# MSS_DEBUGSS register map
Vendor: Texas Instruments
Peripheral module from a debugger description file (folder awr29xx).
Registers are 32-bit, read-write, no defined reset value unless marked. A register's access mark holds for its fields unless they carry their own. Offsets are as the file gives them; lines under a group give offsets from that group; [hi:lo] are bit positions; {n}, {i} and the like mark numbered series; 'fields as' and 'values as' point back to an identical list; <NAME> marks a mode.

## MSS_DEBUGSS (part 1 of 2)
0x00 ONEMCU_APB_BASE ro — Start Address of ROM Table
  [31:0] ONEMCU_APB_BASE — OneMCU APB Space : Start Address of ROM Table
0xFFC ONEMCU_APB_BASE_END ro — End Address of ROM Table
  [31:0] ONEMCU_APB_BASE_END — OneMCU APB Space : Endt Address of ROM Table
0x1000 ONEMCU_CTI_CONTROL — http://infocenter.arm.com/help/topic/com.arm.doc.ddi0314h/Chdjefbi.html http://infocenter.arm.com/help/topic/com.arm.doc.ddi0314h/Chdefejc.html
  [31:0] ONEMCU_CTI_CONTROL — http://infocenter.arm.com/help/topic/com.arm.doc.ddi0480e/CHDGDIHE.html http://infocenter.arm.com/help/topic/com.arm.doc.ddi0480e/CHDHBDIA.html
0x1010 ONEMCU_CTI_INTACK wo
0x1014 ONEMCU_CTI_APPSET
0x1018 ONEMCU_CTI_APPCLEAR wo
0x101C ONEMCU_CTI_APPPULSE wo
{0x1020+4i} ONEMCU_CTI_INEN{i} (i=0..7)
{0x10A0+4i} ONEMCU_CTI_OUTEN{i} (i=0..7)
0x1130 ONEMCU_CTI_TRIGINSTATUS ro
0x1134 ONEMCU_CTI_TRIGOUTSTATUS ro
0x1138 ONEMCU_CTI_CHINSTATUS ro
0x113C ONEMCU_CTI_CHOUTSTATUS ro
0x1140 ONEMCU_CTI_GATE
0x1144 ONEMCU_CTI_ASICCTL
0x1EDC ONEMCU_CTI_ITCHINACK wo
0x1EE0 ONEMCU_CTI_ITTRIGINACK wo
0x1EE4 ONEMCU_CTI_ITCHOUT wo
0x1EE8 ONEMCU_CTI_ITTRIGOUT wo
0x1EEC ONEMCU_CTI_ITCHOUTACK ro
0x1EF0 ONEMCU_CTI_ITTRIGOUTACK ro
0x1EF4 ONEMCU_CTI_ITCHIN ro
0x1EF8 ONEMCU_CTI_ITTRIGIN ro
0x1F00 ONEMCU_CTI_ITCTRL
0x1FA0 ONEMCU_CTI_Claim_Tag_Set
0x1FA4 ONEMCU_CTI_Claim_Tag_Clear
0x1FB0 ONEMCU_CTI_Lock_Access_Register wo
0x1FB4 ONEMCU_CTI_Lock_Status_Register ro
0x1FB8 ONEMCU_CTI_Authentication_Status ro
0x1FC8 ONEMCU_CTI_Device_ID ro
0x1FCC ONEMCU_CTI_Device_Type_Identifier ro
{0x1FC0+4i} ONEMCU_CTI_PeripheralID{i} ro (i=4..7)
{0x1FE0+4i} ONEMCU_CTI_PeripheralID{i} ro (i=0..3)
{0x1FF0+4i} ONEMCU_CTI_Component_ID{i} ro (i=0..3)
0x2000 ONEMCU_TPIU_SPORTSZ ro — Supported port sizes
0x2004 ONEMCU_TPIU_CPORTSZ — Current port size
0x2100 ONEMCU_TPIU_STRIGM ro — Supported trigger modes
0x2104 ONEMCU_TPIU_TRIGCNT — Trigger counter value
0x2108 ONEMCU_TPIU_TRIGMUL — Trigger multiplier
0x2200 ONEMCU_TPIU_STSTPTRN ro — Supported test pattern/modes
0x2204 ONEMCU_TPIU_CTSTPTRN — Current test pattern/mode
0x2208 ONEMCU_TPIU_TPRCNTR — Test pattern repeat counter
0x2300 ONEMCU_TPIU_FFSTS ro — Formatter and flush status
0x2304 ONEMCU_TPIU_FFCTRL — Formatter and flush control
0x2308 ONEMCU_TPIU_FSCNTR — Formatter synchronization counter
0x2400 ONEMCU_TPIU_EXCTLIN ro — EXTCTL In Port
0x2404 ONEMCU_TPIU_EXCTLOUT — EXTCTL Out Port
0x2EE4 ONEMCU_TPIU_ITTRFLINACK wo — Integration Register, ITTRFLINACK
0x2EE8 ONEMCU_TPIU_ITTRFLIN ro — Integration Register, ITTRFLIN
0x2EEC ONEMCU_TPIU_ITATBDATA0 ro — Integration Register, ITATBDATA0
0x2EF0 ONEMCU_TPIU_ITATBCTR2 wo — Integration Register, ITATBCTR2
0x2EF4 ONEMCU_TPIU_ITATBCTR1 ro — Integration Register, ITATBCTR1
0x2EF8 ONEMCU_TPIU_ITATBCTR0 ro — Integration Register, ITATBCTR0
0x2F00 ONEMCU_TPIU_ITCTRL — Integration Mode Control Register
0x2FA0 ONEMCU_TPIU_CLAIMSET — Claim Tag Set
0x2FA4 ONEMCU_TPIU_CLAIMCLR — Claim Tag Clear
0x2FB0 ONEMCU_TPIU_LAR ro — Lock status
0x2FB4 ONEMCU_TPIU_LSR wo — Lock Access
0x2FB8 ONEMCU_TPIU_AUTHSTATUS ro — Authentication status
0x2FC8 ONEMCU_TPIU_DEVID ro — Device ID
0x2FCC ONEMCU_TPIU_DEVTYPE ro — Device type identifier
{0x2FC0+4i} ONEMCU_TPIU_PIDR{i} ro (i=4..7) — Peripheral ID{i}
{0x2FE0+4i} ONEMCU_TPIU_PIDR{i} ro (i=0..3) — Peripheral ID{i}
{0x2FF0+4i} ONEMCU_TPIU_CIDR{i} ro (i=0..3) — Component ID{i}
0x10000 GEM_ADTF_CSR
  [31:0] GEM_ADTF_CSR — Control & Status Register
0x10400 GEM_ADTF_TRACE_ID
  [31:0] GEM_ADTF_TRACE_ID — Trace ID
0x10FA0 GEM_ADTF_MR_CLAIMSET — Claim Tag Set Register
0x10FA4 GEM_ADTF_MR_CLAIMCLR — Claim Tag Clear Register
0x10FB0 GEM_ADTF_MR_LOCKACCESS — Lock Access Register
0x10FB4 GEM_ADTF_MR_LOCKSTATUS — Lock Status Register
0x10FB8 GEM_ADTF_MR_AUTHSTATUS — Authentication Status Register
0x10FC8 GEM_ADTF_MR_DEVID — Device Identifier
0x10FCC GEM_ADTF_MR_DEVTYPE — Device Type Register
{0x10FC0+4i} GEM_ADTF_PERIP_ID{i} (i=4..7)
  [31:0] GEM_ADTF_PERIP_ID{i} — Peripheral ID
{0x10FE0+4i} GEM_ADTF_PERIP_ID{i} (i=0..3)
  [31:0] GEM_ADTF_PERIP_ID{i} — Peripheral ID
{0x10FF0+4i} GEM_ADTF_COMP_ID{i} (i=0..3)
  [31:0] GEM_ADTF_COMP_ID{i} — Component ID
0x11000 GEM_ATB_IDFILTER0 — ID filtering for ATB master port 0
  [31:0] GEM_ATB_IDFILTER0 — http://infocenter.arm.com/help/topic/com.arm.doc.ddi0480e/CHDFGIED.html http://infocenter.arm.com/help/topic/com.arm.doc.ddi0480e/CHDBDCII.html
0x11004 GEM_ATB_IDFILTER1 — ID filtering for ATB master port 1
0x11EF8 GEM_ATB_ITATBCTR1 ro — Integration Mode ATB Control 1 Register
0x11EFC GEM_ATB_ITATBCTR0 wo — Integration Mode ATB Control 0 Register
0x11F00 GEM_ATB_ITCTRL — Integration Mode Control Register
0x11FA0 GEM_ATB_CLAIMSET — Claim Tag Set Register
0x11FA4 GEM_ATB_CLAIMCLR — Claim Tag Clear Register
0x11FB0 GEM_ATB_LAR wo — Lock Access Register
0x11FB4 GEM_ATB_LSR ro — Lock Status
0x11FB8 GEM_ATB_AUTHSTATUS ro — Authentication Status Register
0x11FC8 GEM_ATB_DEVID ro — Device Configuration Register
0x11FCC GEM_ATB_DEVTYPE ro — Device Type Identifier Register
0x11FD0 GEM_ATB_PIDR4 ro — Peripheral ID4 Register
{0x11FD0+4i} GEM_ATB_RESERVED{i} ro (i=1..3) — Reserved
{0x11FE0+4i} GEM_ATB_PIDR{i} ro (i=0..3) — Peripheral ID{i} Register
{0x11FF0+4i} GEM_ATB_CIDR{i} ro (i=0..3) — Component ID{i} Register
0x12000 MSS_ATB_IDFILTER0 — ID filtering for ATB master port 0
  [31:0] MSS_ATB_IDFILTER0 — http://infocenter.arm.com/help/topic/com.arm.doc.ddi0480e/CHDFGIED.html http://infocenter.arm.com/help/topic/com.arm.doc.ddi0480e/CHDBDCII.html
0x12004 MSS_ATB_IDFILTER1 — ID filtering for ATB master port 1
0x12EF8 MSS_ATB_ITATBCTR1 ro — Integration Mode ATB Control 1 Register
0x12EFC MSS_ATB_ITATBCTR0 wo — Integration Mode ATB Control 0 Register
0x12F00 MSS_ATB_ITCTRL — Integration Mode Control Register
0x12FA0 MSS_ATB_CLAIMSET — Claim Tag Set Register
0x12FA4 MSS_ATB_CLAIMCLR — Claim Tag Clear Register
0x12FB0 MSS_ATB_LAR wo — Lock Access Register
0x12FB4 MSS_ATB_LSR ro — Lock Status
0x12FB8 MSS_ATB_AUTHSTATUS ro — Authentication Status Register
0x12FC8 MSS_ATB_DEVID ro — Device Configuration Register
0x12FCC MSS_ATB_DEVTYPE ro — Device Type Identifier Register
0x12FD0 MSS_ATB_PIDR4 ro — Peripheral ID4 Register
{0x12FD0+4i} MSS_ATB_RESERVED{i} ro (i=1..3) — Reserved
{0x12FE0+4i} MSS_ATB_PIDR{i} ro (i=0..3) — Peripheral ID{i} Register
{0x12FF0+4i} MSS_ATB_CIDR{i} ro (i=0..3) — Component ID{i} Register
0x13004 ETB_RDP ro — ETBRAMDepthRegister
  [31:0] ETB_RDP — http://infocenter.arm.com/help/topic/com.arm.doc.ddi0480e/CHDIEIAJ.html http://infocenter.arm.com/help/topic/com.arm.doc.ddi0480e/CHDDBEHG.html
0x1300C ETB_STS ro — ETBStatusRegister
0x13010 ETB_RRD ro — ETBRAMReadDataRegister
0x13014 ETB_RRP — ETBRAMReadPointerRegister
0x13018 ETB_RWP — ETBRAMWritePointerRegister
0x1301C ETB_TRG — ETBTriggerCounterRegister
0x13020 ETB_CTL — ETBControlRegister
0x13024 ETB_RWD wo — ETBRAMWriteDataRegister
0x13300 ETB_FFSR ro — ETBFormatterandFlushStatusRegister
0x13304 ETB_FFCR — ETBFormatterandFlushControlRegister
0x13EE0 ETB_ITMISCOP0 wo — IntegrationTestMiscellaneousOutputRegister0
0x13EE4 ETB_ITTRFLINACK wo — IntegrationTestTriggerInandFlushInAcknowledgeRegister
0x13EE8 ETB_ITTRFLIN ro — IntegrationTestTriggerInandFlushInRegister
0x13EEC ETB_ITATBDATA0 ro — IntegrationTestATBDataRegister0
0x13EF0 ETB_ITATBCTR2 wo — IntegrationTestATBControlRegister2
0x13EF4 ETB_ITATBCTR1 ro — IntegrationTestATBControlRegister1
0x13EF8 ETB_ITATBCTR0 ro — IntegrationTestATBControlRegister0
0x13F00 ETB_ITCTRL — IntegrationModeControlRegister
0x13FA0 ETB_CLAIMSET — ClaimTagSetRegister
0x13FA4 ETB_CLAIMCLR — ClaimTagClearRegister
0x13FB0 ETB_LAR wo — LockAccessRegister
0x13FB4 ETB_LSR ro — LockStatusRegister
0x13FB8 ETB_AUTHSTATUS ro — AuthenticationStatusRegister
0x13FC8 ETB_DEVID ro — DeviceConfigurationRegister
0x13FCC ETB_DEVTYPE ro — DeviceTypeIdentifierRegister
0x13FD0 ETB_PIDR4 ro — PeripheralID4Register
{0x13FC4+4i} ETB_RESERVED{i} ro (i=4..6) — Reserved
{0x13FE0+4i} ETB_PIDR{i} ro (i=0..3) — PeripheralID{i}Register
{0x13FF0+4i} ETB_CIDR{i} ro (i=0..3) — ComponentID{i}Register
0x14000 DSS_CM4_ATB_IDFILTER0 — ID filtering for ATB master port 0
  [31:0] DSS_CM4_ATB_IDFILTER0 — http://infocenter.arm.com/help/topic/com.arm.doc.ddi0480e/CHDFGIED.html http://infocenter.arm.com/help/topic/com.arm.doc.ddi0480e/CHDBDCII.html
0x14004 DSS_CM4_ATB_IDFILTER1 — ID filtering for ATB master port 1
0x14EF8 DSS_CM4_ATB_ITATBCTR1 ro — Integration Mode ATB Control 1 Register
0x14EFC DSS_CM4_ATB_ITATBCTR0 wo — Integration Mode ATB Control 0 Register
0x14F00 DSS_CM4_ATB_ITCTRL — Integration Mode Control Register
0x14FA0 DSS_CM4_ATB_CLAIMSET — Claim Tag Set Register
0x14FA4 DSS_CM4_ATB_CLAIMCLR — Claim Tag Clear Register
0x14FB0 DSS_CM4_ATB_LAR wo — Lock Access Register
0x14FB4 DSS_CM4_ATB_LSR ro — Lock Status
0x14FB8 DSS_CM4_ATB_AUTHSTATUS ro — Authentication Status Register
0x14FC8 DSS_CM4_ATB_DEVID ro — Device Configuration Register
0x14FCC DSS_CM4_ATB_DEVTYPE ro — Device Type Identifier Register
0x14FD0 DSS_CM4_ATB_PIDR4 ro — Peripheral ID4 Register
{0x14FD0+4i} DSS_CM4_ATB_RESERVED{i} ro (i=1..3) — Reserved
{0x14FE0+4i} DSS_CM4_ATB_PIDR{i} ro (i=0..3) — Peripheral ID{i} Register
{0x14FF0+4i} DSS_CM4_ATB_CIDR{i} ro (i=0..3) — Component ID{i} Register
0x15000 HSM_CM4_ATB_IDFILTER0 — ID filtering for ATB master port 0
  [31:0] HSM_CM4_ATB_IDFILTER0 — http://infocenter.arm.com/help/topic/com.arm.doc.ddi0480e/CHDFGIED.html http://infocenter.arm.com/help/topic/com.arm.doc.ddi0480e/CHDBDCII.html
0x15004 HSM_CM4_ATB_IDFILTER1 — ID filtering for ATB master port 1
0x15EF8 HSM_CM4_ATB_ITATBCTR1 ro — Integration Mode ATB Control 1 Register
0x15EFC HSM_CM4_ATB_ITATBCTR0 wo — Integration Mode ATB Control 0 Register
0x15F00 HSM_CM4_ATB_ITCTRL — Integration Mode Control Register
0x15FA0 HSM_CM4_ATB_CLAIMSET — Claim Tag Set Register
0x15FA4 HSM_CM4_ATB_CLAIMCLR — Claim Tag Clear Register
0x15FB0 HSM_CM4_ATB_LAR wo — Lock Access Register
0x15FB4 HSM_CM4_ATB_LSR ro — Lock Status
0x15FB8 HSM_CM4_ATB_AUTHSTATUS ro — Authentication Status Register
0x15FC8 HSM_CM4_ATB_DEVID ro — Device Configuration Register
0x15FCC HSM_CM4_ATB_DEVTYPE ro — Device Type Identifier Register
0x15FD0 HSM_CM4_ATB_PIDR4 ro — Peripheral ID4 Register
{0x15FD0+4i} HSM_CM4_ATB_RESERVED{i} ro (i=1..3) — Reserved
{0x15FE0+4i} HSM_CM4_ATB_PIDR{i} ro (i=0..3) — Peripheral ID{i} Register
{0x15FF0+4i} HSM_CM4_ATB_CIDR{i} ro (i=0..3) — Component ID{i} Register
0x16C04 STMDMASTARTR wo — ARM® System Trace Macrocell Programmers’ Model Architecture Specification
0x16C08 STMDMASTOPR wo — ARM® System Trace Macrocell Programmers’ Model Architecture Specification
0x16C0C STMDMASTATR ro — ARM® System Trace Macrocell Programmers’ Model Architecture Specification
0x16C10 STMDMACTLR 4-bit — Controls the DMA transfer request mechanism.
  [3:2] SENS — Determines the sensitivity of the DMA request to the current buffer level in the STM: 0b00 Buffer is <25% full. 0b01 Buffer is <50% full. 0b10 Buffer is <75% full. 0b11 Buffer is <100% full.
0x16CFC STMDMAIDR ro — ARM® System Trace Macrocell Programmers’ Model Architecture Specification
0x16D00 STMHEER — ARM® System Trace Macrocell Programmers’ Model Architecture Specification
0x16D20 STMHETER — ARM® System Trace Macrocell Programmers’ Model Architecture Specification
0x16D60 STMHEBSR — ARM® System Trace Macrocell Programmers’ Model Architecture Specification
0x16D64 STMHEMCR — ARM® System Trace Macrocell Programmers’ Model Architecture Specification
0x16D68 STMHEEXTMUXR 8-bit — Hardware Event External Multiplex Control Register
  [7:0] EXTMUX — Specifies the value that the optional external multiplexing logic uses to select the hardware events to connect to the STM. The value of this register is output from the STM on the HEEXTMUX[7:0] signals. The behavior of the multiplexing logic is IMPLEMENTATION DEFINED. This field is reset to zero.
0x16DF4 STMHEMASTR 16-bit ro — Hardware Event Master Number Register
  [15:0] MASTER — The STPv2 master number for the hardware event trace: 0x80 Hardware events are associated with master ID 0x80.
0x16DF8 STMHEFEAT1R 31-bit ro — Hardware Event Features 1 Register
  [30:28] HEEXTMUXSIZE — The size of the STMHEEXTMUXR.EXTMUX bit field: 0b011 8 bits wide.
  [23:15] NUMHE — The number of hardware events supported by the STM: 0b001000000 64 hardware events.
  [5:4] HECOMP — Data compression on hardware event tracing support: 0b11 Programmable data compression support. The STM implements the STMHEMCR.COMPEN bit.
  [3] HEMASTR — Specifies the STMHEMASTR support: 0b0 The STMHEMASTR is read-only.
  [2] HEERR — Hardware event error detection support: 0b1 Implemented. The STM implements the STMHEMCR.ERRDETECT bit.
  [0] HETER — Specifies the STMHETER support: 0b1 Implemented.
0x16DFC STMHEIDR 12-bit ro — Hardware Event ID Register
  [11:8] VENDSPEC — Identifies vendor-specific modifications or mappings: 0b0000 Vendor-specific information.
  [7:4] CLASSREV — Identifies the revision of the programmers model: 0b0001 Revision.
  [3:0] CLASS — Identifies the programmers model: 0b0001 Hardware event control.
0x16E00 STMSPER — ARM® System Trace Macrocell Programmers’ Model Architecture Specification
0x16E20 STMSPTER — ARM® System Trace Macrocell Programmers’ Model Architecture Specification
0x16E60 STMSPSCR — ARM® System Trace Macrocell Programmers’ Model Architecture Specification
0x16E64 STMSPMSCR — ARM® System Trace Macrocell Programmers’ Model Architecture Specification
0x16E68 STMSPOVERRIDER — ARM® System Trace Macrocell Programmers’ Model Architecture Specification
0x16E6C STMSPMOVERRIDER — ARM® System Trace Macrocell Programmers’ Model Architecture Specification
0x16E70 STMSPTRIGCSR — ARM® System Trace Macrocell Programmers’ Model Architecture Specification
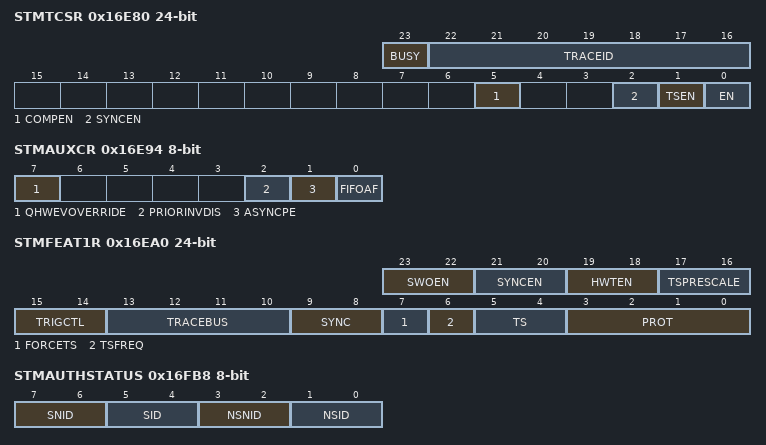
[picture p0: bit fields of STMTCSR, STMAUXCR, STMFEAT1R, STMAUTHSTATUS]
0x16E80 STMTCSR 24-bit — Trace Control and Status Register
  [23] BUSY — Indicates whether the STM is busy, for example the STM trace FIFO is not empty: 0b0 Not busy. 0b1 Busy.
  [22:16] TRACEID — ATB trace ID. Setting this value to all zeroes or to a value greater than 0x6F might result in UNPREDICTABLE tracing. Reset value of this bit field is UNKNOWN.
  [5] COMPEN — Compression enable for stimulus ports: 0b0 Disabled, the STM transmits data transfers based on the size of the transaction. 0b1 Enabled, the STM compresses data transfers to save bandwidth.
  [2] SYNCEN — The STM implements the STMSYNCR, so this bit is Read As One. 0b1 The STM implements the STMSYNCR.
  [1] TSEN — Determines whether to ignore timestamp requests: 0b0 Disable timestamping. The STM ignores requests for timestamp generation, and treats stimulus port writes that select timestamping as if timestamping were not selected. 0b1 Enable timestamping. If stimulus writes select timestamping, the STM outputs a timestamp according to STPv2.
  [0] EN — Global STM enable: 0b0 Disabled 0b1 Enabled.
0x16E84 STMTSSTIMR wo — ARM® System Trace Macrocell Programmers’ Model Architecture Specification
0x16E8C STMTSFREQR — ARM® System Trace Macrocell Programmers’ Model Architecture Specification
0x16E90 STMSYNCR — ARM® System Trace Macrocell Programmers’ Model Architecture Specification
0x16E94 STMAUXCR 8-bit — Auxiliary Control Register
  [7] QHWEVOVERRIDE — Low-power interface override when hardware event tracing is enabled: 0b0 The STM can accept a quiescence request on the STM low-power interface when the STMHEMCR.EN bit is set to 0b1. 0b1 If the STMHEMCR.EN bit is set to 0b1, all quiescence requests on the STM low-power interface are denied. Reset value is 0b0.
  [2] PRIORINVDIS — Controls arbitration between the AXI interface and the hardware event observation interface during flush: 0b0 Priority inversion. When the AXI flush completes, the hardware event observation interface gets priority until the hardware event observation interface flush completes. 0b1 Priority inversion disabled. The AXI always has priority over the hardware event observation interface. Reset value is 0b0.
  [1] ASYNCPE — ASYNC priority: 0b0 Always lower than trace. 0b1 Escalates on second synchronization request. Reset value is 0b0.
  [0] FIFOAF — Auto-flush: 0b0 Disabled. 0b1 Enabled. The STM automatically drains all data even if the ATB interface is not fully utilized. Reset value is 0b0.
0x16EA0 STMFEAT1R 24-bit ro — STM Features 1 Register
  [23:22] SWOEN — Specifies the STMTCSR.SWOEN bit support: 0b01 Not implemented.
  [21:20] SYNCEN — Specifies the STMTCSR.SYNCEN bit support: 0b10 Implemented but always reads as 0b1.
  [19:18] HWTEN — Specifies the STMTCSR.HWTEN bit support: 0b01 Not implemented.
  [17:16] TSPRESCALE — Timestamp prescale support: 0b01 Not implemented.
  [15:14] TRIGCTL — Trigger control support: 0b10 Multi-shot and single-shot triggers supported, the STM implements the STMTRIGCSR.
  [13:10] TRACEBUS — Trace bus support: 0b0001 CoreSight ATB plus ATB trigger support implemented, the STM implements the STMTCSR.TRACEID and STMTRIGCSR.ATBTRIGEN bit fields.
  [9:8] SYNC — Specifies the STMSYNCR support: 0b11 Implemented with MODE control.
  [7] FORCETS — Specifies the STMTSSTIMR support: 0b1 The STM implements the STMTSSTIMR.FORCETS bit.
  [6] TSFREQ — Timestamp frequency indication configuration: 0b1 The STMTSFREQR is read-write.
  [5:4] TS — Timestamp support: 0b01 Absolute timestamps implemented.
  [3:0] PROT — Protocol: 0b0001 STPv2 protocol.
0x16EA4 STMFEAT2R 18-bit ro — STM Features 2 Register
  [17:16] SPTYPE — Stimulus port type support: 0b01 Only extended stimulus ports.
  [15:12] DSIZE — Fundamental data size: 0b0001 64-bit data.
  [10:9] SPTRTYPE — Stimulus port transaction type support: 0b10 Both invariant timing and guaranteed transactions.
  [8:7] PRIVMASK — Specifies the STMPRIVMASKR support: 0b01 Not implemented.
  [6] SPOVERRIDE — Specifies the STMSPOVERRIDER support: 0b1 STMSPOVERRIDER and STMSPMOVERRIDER implemented.
  [5:4] SPCOMP — Data compression on stimulus ports support: 0b11 Data compression support is programmable, the STM implements the STMTCSR.COMPEN bit.
  [2] SPER — Specifies the STMSPER presence: 0b0 Implemented.
  [1:0] SPTER — Specifies the STMSPTER support: 0b10 Implemented.
0x16EA8 STMFEAT3R 7-bit ro — STM Features 3 Register
  [6:0] NUMMAST — The number of stimulus port masters implemented minus 1: 0b1111111 128 ports.
0x16EE8 STMITTRIGGER 4-bit wo — Integration Test for Cross-Trigger Outputs Register
  [3] ASYNCOUT_W — Sets the value of the ASYNCOUT output signal in integration mode: 0b1 Drive logic 0b1. 0b0 Drive logic 0b0.
  [2] TRIGOUTHETE_W — Sets the value of the TRIGOUTHETE output signal in integration mode: 0b1 Drive logic 0b1. 0b0 Drive logic 0b0.
  [1] TRIGOUTSW_W — Sets the value of the TRIGOUTSW output signal in integration mode: 0b1 Drive logic 0b1. 0b0 Drive logic 0b0.
  [0] TRIGOUTSPTE_W — Sets the value of the TRIGOUTSPTE output signal in integration mode: 0b1 Drive logic 0b1. 0b0 Drive logic 0b0.
0x16EEC STMITATBDATA0 9-bit wo — Integration Mode ATB Data 0 register
  [8] ATDATAM63_W — Sets the value of the ATDATAM[63] output signal: 0b1 Drive logic 0b1. 0b0 Drive logic 0b0.
  [7] ATDATAM55_W — Sets the value of the ATDATAM[55] output signal: 0b1 Drive logic 0b1. 0b0 Drive logic 0b0.
  [6] ATDATAM47_W — Sets the value of the ATDATAM[47] output signal: 0b1 Drive logic 0b1. 0b0 Drive logic 0b0.
  [5] ATDATAM39_W — Sets the value of the ATDATAM[39] output signal: 0b1 Drive logic 0b1. 0b0 Drive logic 0b0.
  [4] ATDATAM31_W — Sets the value of the ATDATAM[31] output signal: 0b1 Drive logic 0b1. 0b0 Drive logic 0b0.
  [3] ATDATAM23_W — Sets the value of the ATDATAM[23] output signal: 0b1 Drive logic 0b1. 0b0 Drive logic 0b0.
  [2] ATDATAM15_W — Sets the value of the ATDATAM[15] output signal: 0b1 Drive logic 0b1. 0b0 Drive logic 0b0.
  [1] ATDATAM7_W — Sets the value of the ATDATAM[7] output signal: 0b1 Drive logic 0b1. 0b0 Drive logic 0b0.
  [0] ATDATAM0_W — Sets the value of the ATDATAM[0] output signal: 0b1 Drive logic 0b1. 0b0 Drive logic 0b0.
0x16EF0 STMITATBCTR2 2-bit ro — Integration Mode ATB Control 2 register
  [1] AFVALIDM_R — Reads the value of the AFVALIDM input signal: 0b1 The signal is at logic 0b1. 0b0 The signal is at logic 0b0.
  [0] ATREADYM_R — Reads the value of the ATREADYM input signal: 0b1 The signal is at logic 0b1. 0b0 The signal is at logic 0b0.
0x16EF4 STMITATBID 7-bit wo — Integration Mode ATB Identification register
  [6:0] ATIDM_W — Sets the value of the ATIDM output signal.
0x16EF8 STMITATBCTR0 11-bit wo — Integration Mode ATB Control 0 register on
  [10:8] ATBYTESM_W — Sets the value of the ATBYTESM output signal: 0b111 Drive logic 0b111. 0b110 Drive logic 0b110. 0b101 Drive logic 0b101. 0b100 Drive logic 0b100. 0b011 Drive logic 0b011. 0b010 Drive logic 0b010. 0b001 Drive logic 0b001. 0b000 Drive logic 0b000.
  [1] AFREADYM_W — Sets the value of the AFREADYM output signal: 0b1 Drive logic 0b1. 0b0 Drive logic 0b0.
  [0] ATVALIDM_W — Sets the value of the ATVALIDM output signal: 0b1 Drive logic 0b1. 0b0 Drive logic 0b0.
0x16F00 STMITCTRL 1-bit — Integration Mode Control register
  [0] IME — Enables the component to switch between functional and integration mode. 0b1 Enable integration mode. 0b0 Disable integration mode.
0x16FA0 STMCLAIMSET — ARM® System Trace Macrocell Programmers’ Model Architecture Specification
0x16FA4 STMCLAIMCLR — ARM® System Trace Macrocell Programmers’ Model Architecture Specification
0x16FB0 STMLAR wo — Lock Access Register
  [31:0] KEY — Ignores writes when the PADDRDBG31 signal is HIGH. When the PADDRDBG31 signal is LOW, a write of 0xC5ACCE55 unlocks the lock control mechanism, enabling further writes with the PADDRDBG31 signal LOW. Other values lock the lock control mechanism, preventing further writes with the PADDRDBG31 signal LOW, except to the STMLAR.
0x16FB4 STMLSR 3-bit wo — Lock Status Register
  [2] nTT — Indicates whether the component implements the STMLAR as 8 bit or 32 bit. 0b0 32 bit.
  [1] SLK — Returns the current status of the lock. 0b0 Enables write access to the STM. For read accesses to the STMLSR when the PADDRDBG31 signal is HIGH, this bit is always 0b0. 0b1 Blocks write access to the STM. The STM ignores all write accesses to the registers when the PADDRDBG31 signal is LOW. Reads are permitted
  [0] SLI — Indicates that a lock control mechanism exists for the device. 0b0 No lock control mechanism exists. The STM ignores writes to the STMLAR. For read accesses to the STMLSR when the PADDRDBG31 signal is HIGH, this bit is always 0b0. 0b1 Lock control mechanism is present. For read accesses to the STMLSR when the PADDRDBG31 signal is LOW, this bit is always 0b1.
0x16FB8 STMAUTHSTATUS 8-bit ro — Authentication Status register
  [7:6] SNID — Indicates the security level for Secure non-invasive debug: 0b10 Disabled. 0b11 Enabled.
  [5:4] SID — Indicates the security level for Secure invasive debug: 0b10 Disabled. 0b11 Enabled.
  [3:2] NSNID — Indicates the security level for Non-secure non-invasive debug: 0b10 Disabled. 0b11 Enabled.
  [1:0] NSID — Indicates the security level for Non-secure invasive debug: 0b10 Disabled. 0b11 Enabled.
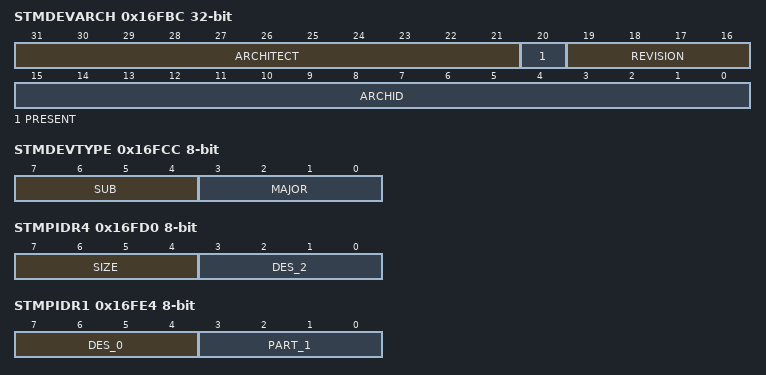
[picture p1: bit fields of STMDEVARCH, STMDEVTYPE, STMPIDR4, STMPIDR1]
0x16FBC STMDEVARCH ro — Device Architecture register
  [31:21] ARCHITECT — Defines the architect of the component: Bits[31:28] Indicates the JEP106 continuation code. Bits[27:21] Indicates the JEP106 identification code. See the Standard Manufacturer’s Identification Code for information about JEP106. For the STM-500, ARM is the architect, and this 11-bit field returns 0x23B.
  [20] PRESENT — Indicates the presence of the STMDEVARCH register: 0b1 The STMDEVARCH register is present.
  [19:16] REVISION — Architecture revision. Returns the revision of the architecture that the ARCHID field specifies. For the STM, this value is 0x1, indicating the STMv1.1 architecture.
  [15:0] ARCHID — Architecture ID. Returns a value that identifies the architecture of the component. For the STM, this value is 0x0A63, indicating the STMv1.1 architecture.
0x16FC8 STMDEVID 17-bit ro — Device Configuration register
  [16:0] NUMSP — Indicates the number of stimulus ports implemented. 0x10000 65536
0x16FCC STMDEVTYPE 8-bit ro — Device Type Identifier register
  [7:4] SUB — Sub-classification within the major category: 0b0110 The component generates trace based on software and hardware stimulus
  [3:0] MAJOR — Major classification grouping for the debug or trace component: 0b0011 The component is a trace source.
0x16FD0 STMPIDR4 8-bit ro — Peripheral ID4
  [7:4] SIZE — This 4-bit value indicates the total contiguous size of the memory window used by the component in powers of two from the standard 4KB. If a component only requires the standard 4KB, this bit field must read as 0x0, 4KB only. For 8KB set to 0x1, for 16KB set to 0x2, for 32KB set to 0x3, and so on. 0x0 The device only occupies 4KB of memory.
  [3:0] DES_2 — JEDEC continuation code indicating the designer of the component, together with the identity code. 0x4 ARM JEDEC identity code is on the fifth bank.
0x16FE0 STMPIDR0 8-bit ro — Peripheral ID0
  [7:0] PART_0 — Bits [7:0] of the component part number, specified by the designer of the component. 0b01100011 Lowest eight bits of the part number, 0x963.
0x16FE4 STMPIDR1 8-bit ro — Peripheral ID1
  [7:4] DES_0 — Bits [3:0] of the JEDEC identity code indicating the designer of the component, together with the continuation code. 0b1011 Lowest four bits of the JEP106 identity code.
  [3:0] PART_1 — Bits [11:8] of the component part number, specified by the designer of the component. 0b1001 Upper four bits of the part number, 0x963.
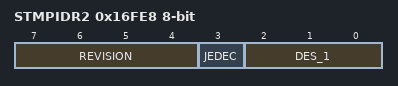
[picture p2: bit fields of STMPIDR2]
0x16FE8 STMPIDR2 8-bit ro — Peripheral ID2
  [7:4] REVISION — An incremental value starting at 0x0 for the first design of this component. The value increases by one for both major and minor revisions and is used as a look-up to establish the exact major and minor revision. 0b0000 The device is at r0p0
  [3] JEDEC — Indicates the use of a JEDEC assigned value. This bit is always set. 0b1 The designer ID is specified by JEDEC (http://www.jedec.org).
  [2:0] DES_1 — Bits [6:4] of the JEDEC identity code indicating the designer of the component, together with the continuation code. 0b011 Upper three bits of the JEP106 identity code
